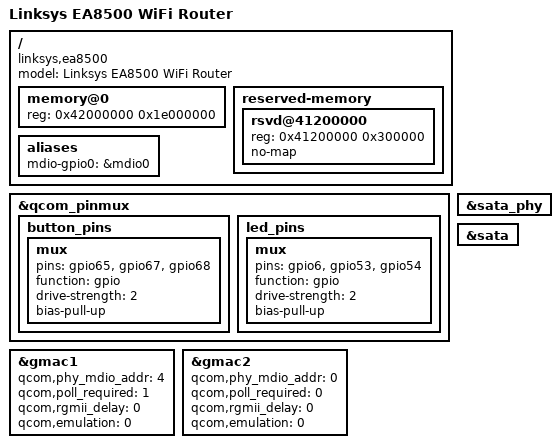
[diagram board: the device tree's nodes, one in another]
#include "qcom-ipq8064-eax500.dtsi"

/ {
	model = "Linksys EA8500 WiFi Router";
	compatible = "linksys,ea8500", "qcom,ipq8064";

	memory@0 {
		reg = <0x42000000 0x1e000000>;
		device_type = "memory";
	};

	reserved-memory {
		#address-cells = <1>;
		#size-cells = <1>;
		ranges;
		rsvd@41200000 {
			reg = <0x41200000 0x300000>;
			no-map;
		};
	};

	aliases {
		mdio-gpio0 = &mdio0;

	};

};

&qcom_pinmux {
	button_pins: button_pins {
		mux {
			pins = "gpio65", "gpio67", "gpio68";
			function = "gpio";
			drive-strength = <2>;
			bias-pull-up;
		};
	};

	led_pins: led_pins {
		mux {
			pins = "gpio6", "gpio53", "gpio54";
			function = "gpio";
			drive-strength = <2>;
			bias-pull-up;
		};
	};
};

&sata_phy {
	status = "okay";
};

&sata {
	status = "okay";
};

&gmac1 {
	qcom,phy_mdio_addr = <4>;
	qcom,poll_required = <1>;
	qcom,rgmii_delay = <0>;
	qcom,emulation = <0>;
};

/* LAN */
&gmac2 {
	qcom,phy_mdio_addr = <0>;	/* none */
	qcom,poll_required = <0>;	/* no polling */
	qcom,rgmii_delay = <0>;
	qcom,emulation = <0>;
};
